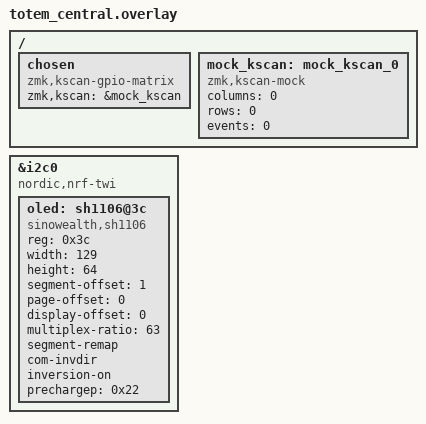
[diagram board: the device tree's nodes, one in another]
/*
 * Copyright (c) 2022 The ZMK Contributors
 *
 * SPDX-License-Identifier: MIT
 */

#include "totem.dtsi"

/ {
    chosen {
        zmk,kscan = &mock_kscan;
    	compatible = "zmk,kscan-gpio-matrix";
    };

    mock_kscan: mock_kscan_0 {
        compatible = "zmk,kscan-mock";
        columns = <0>;
        rows = <0>;
        events = <0>;
    };
};

&i2c0 {
	status = "okay";
	compatible = "nordic,nrf-twi";
	oled: sh1106@3c {
        compatible = "sinowealth,sh1106";
        reg = <0x3c>;
        width = <129>;
        height = <64>;
        segment-offset = <1>;
        page-offset = <0>;
        display-offset = <0>;
        multiplex-ratio = <63>;
        segment-remap;
        com-invdir;
        inversion-on;
        prechargep = <0x22>;
	};
};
